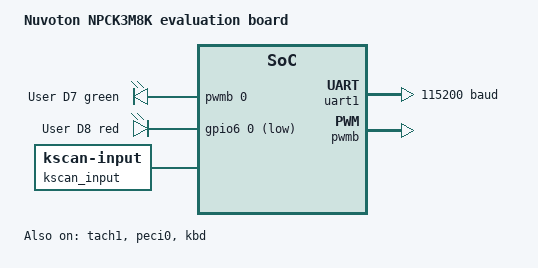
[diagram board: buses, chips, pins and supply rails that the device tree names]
/*
 * Copyright (c) 2025 Nuvoton Technology Corporation.
 *
 * SPDX-License-Identifier: Apache-2.0
 */

/dts-v1/;

#include <nuvoton/npck3m8k.dtsi>
#include "npck3m8k_evb-pinctrl.dtsi"

/ {
	model = "Nuvoton NPCK3M8K evaluation board";

	chosen {
		zephyr,sram = &sram0;
		zephyr,console = &uart1;
		zephyr,shell-uart = &uart1;
		zephyr,flash = &flash0;
		zephyr,keyboard-scan = &kscan_input;
	};

	aliases {
		/* For samples/basic/blinky_pwm */
		pwm-led0 = &pwm_led0_green;

		/* For gpio test suites */
		led0 = &gpio_led_red;

		/* For pwm test suites */
		pwm-0 = &pwmb;

		/* For i2c test suites */
		i2c-0 = &i2c1_a;

		/* For watchdog sample */
		watchdog0 = &twd0;

		/* For peci driver sample code */
		peci-0 = &peci0;

		/* For kscan test suites */
		kscan0 = &kscan_input;
	};

	leds-pwm {
		compatible = "pwm-leds";

		pwm_led0_green: pwm_led_0 {
			pwms = <&pwmb 0 PWM_MSEC(20) PWM_POLARITY_INVERTED>;
			label = "User D7 green";
		};
	};

	leds-gpio {
		compatible = "gpio-leds";

		gpio_led_red: led_0 {
			gpios = <&gpio6 0 GPIO_ACTIVE_LOW>;
			label = "User D8 red";
		};
	};
};

&cpu0 {
	cpu-power-states = <&suspend_to_idle0 &suspend_to_idle1>;
};

/* Overwrite default device properties with overlays in board dt file here. */

&qspi_fiu0 {
	status = "disabled";
};

&uart1 {
	status = "okay";
	current-speed = <115200>;

	/* Use UART1_SL1 ie. PIN83.88 */
	pinctrl-0 = <&uart1_sin_gp87
		     &uart1_sout_gp83>;
	pinctrl-names = "default";
};

&pwmb {
	status = "okay";
	pinctrl-0 = <&pwmb_gp21>;
	pinctrl-names = "default";
};

&adc0 {
	status = "disabled";

	/* Use adc0 channel 0 and 2 for 'adc_api' driver tests */
	pinctrl-0 = <&adc0_chan0_gp90
		     &adc0_chan2_gp92>;
	pinctrl-names = "default";
};

&espi0 {
	status = "disabled";
	pinctrl-0 = <&espi_lpc_gp10_f7>;
	pinctrl-names = "default";
};

&i2c1_a {
	status = "disabled";
	pinctrl-0 = <&i2c1_a_sda_scl_gp22_17>;
	pinctrl-names = "default";
	clock-frequency = <I2C_BITRATE_FAST>;
};

&i2c_ctrl1 {
	status = "disabled";
};

&tach1 {
	status = "okay";
	pinctrl-0 = <&ta1_1_in_gp56>;
	pinctrl-names = "default";
	port = <NPCX_TACH_PORT_A>; /* port-A is selected */
	sample-clk = <NPCX_TACH_FREQ_LFCLK>; /* Use LFCLK as sampling clock */
	pulses-per-round = <1>; /* number of pulses per round of encoder */
};

&peci0 {
	status = "okay";
	pinctrl-0 = <>;
	pinctrl-names = "default";
};

&kbd {
	/* Demonstrate a 13 x 8 keyboard matrix on evb */
	pinctrl-0 = <&ksi0_1_2_3_gpa0_a1_a2_a3 /* KSI0/1/2/3 PINA0/A1/A2/A3 */
		     &ksi4_5_gpa4_a5 /* KSI4/5 PINA4/A5 */
		     &ksi6_7_gpa6_a7 /* KSI6/7 PINA6/A7 */
		     &kso00_01_02_03_gpb0_b1_b2_b3 /* KSO00/01/02/03 PINB0/B1/B2/B3 */
		     &kso04_05_06_07_gpb4_b5_b6_b7 /* KS004/05/06/07 PINB4/B5/B6/B7 */
		     &kso08_09_gpc0_c1 /* KSO08/09 PINC0/C1 */
		     &kso10_11_gpc2_c3 /* KSO10/11 PINC2/C3 */
		     &kso12_gp64 /* KSO12 PIN64 */ >;
	pinctrl-names = "default";
	row-size = <8>;
	col-size = <13>;
	status = "okay";

	kscan_input: kscan-input {
		compatible = "zephyr,kscan-input";
	};
};
